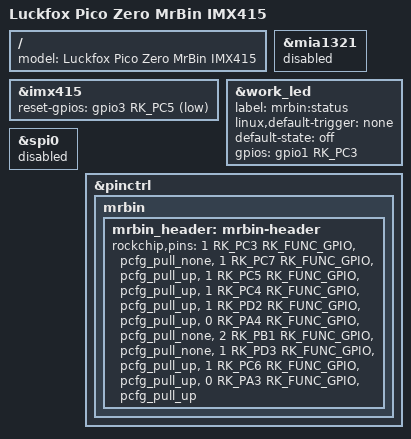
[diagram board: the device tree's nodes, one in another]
// SPDX-License-Identifier: (GPL-2.0+ OR MIT)
/*
 * Overlay MrBin per Luckfox Pico Zero.
 * Si compila solo dentro l'SDK Luckfox, che fornisce rv1106g-luckfox-pico-zero.dts.
 * IMX415 4 lane al posto di SC3336. MIA1321 spento. WiFi SDIO e eMMC non si toccano.
 */
#include "rv1106g-luckfox-pico-zero.dts"

/ {
	model = "Luckfox Pico Zero MrBin IMX415";
};

&mia1321 {
	status = "disabled";
};

&imx415 {
	status = "okay";
	reset-gpios = <&gpio3 RK_PC5 GPIO_ACTIVE_LOW>;
};

&work_led {
	label = "mrbin:status";
	linux,default-trigger = "none";
	default-state = "off";
	/* Pin 21. GPIO3_C6 resta il USER LED di scheda e non è questo LED. */
	gpios = <&gpio1 RK_PC3 GPIO_ACTIVE_HIGH>;
};

&spi0 {
	status = "disabled";
};

&pinctrl {
	mrbin {
		mrbin_header: mrbin-header {
			rockchip,pins =
				/* LED esterno, pin 21, GPIO1_C3. Non il USER LED GPIO3_C6. */
				<1 RK_PC3 RK_FUNC_GPIO &pcfg_pull_none>,
				<1 RK_PC7 RK_FUNC_GPIO &pcfg_pull_up>,
				<1 RK_PC5 RK_FUNC_GPIO &pcfg_pull_up>,
				<1 RK_PC4 RK_FUNC_GPIO &pcfg_pull_up>,
				<1 RK_PD2 RK_FUNC_GPIO &pcfg_pull_up>,
				<0 RK_PA4 RK_FUNC_GPIO &pcfg_pull_none>,
				<2 RK_PB1 RK_FUNC_GPIO &pcfg_pull_none>,
				<1 RK_PD3 RK_FUNC_GPIO &pcfg_pull_up>,
				<1 RK_PC6 RK_FUNC_GPIO &pcfg_pull_up>,
				<0 RK_PA3 RK_FUNC_GPIO &pcfg_pull_up>;
		};
	};
};
